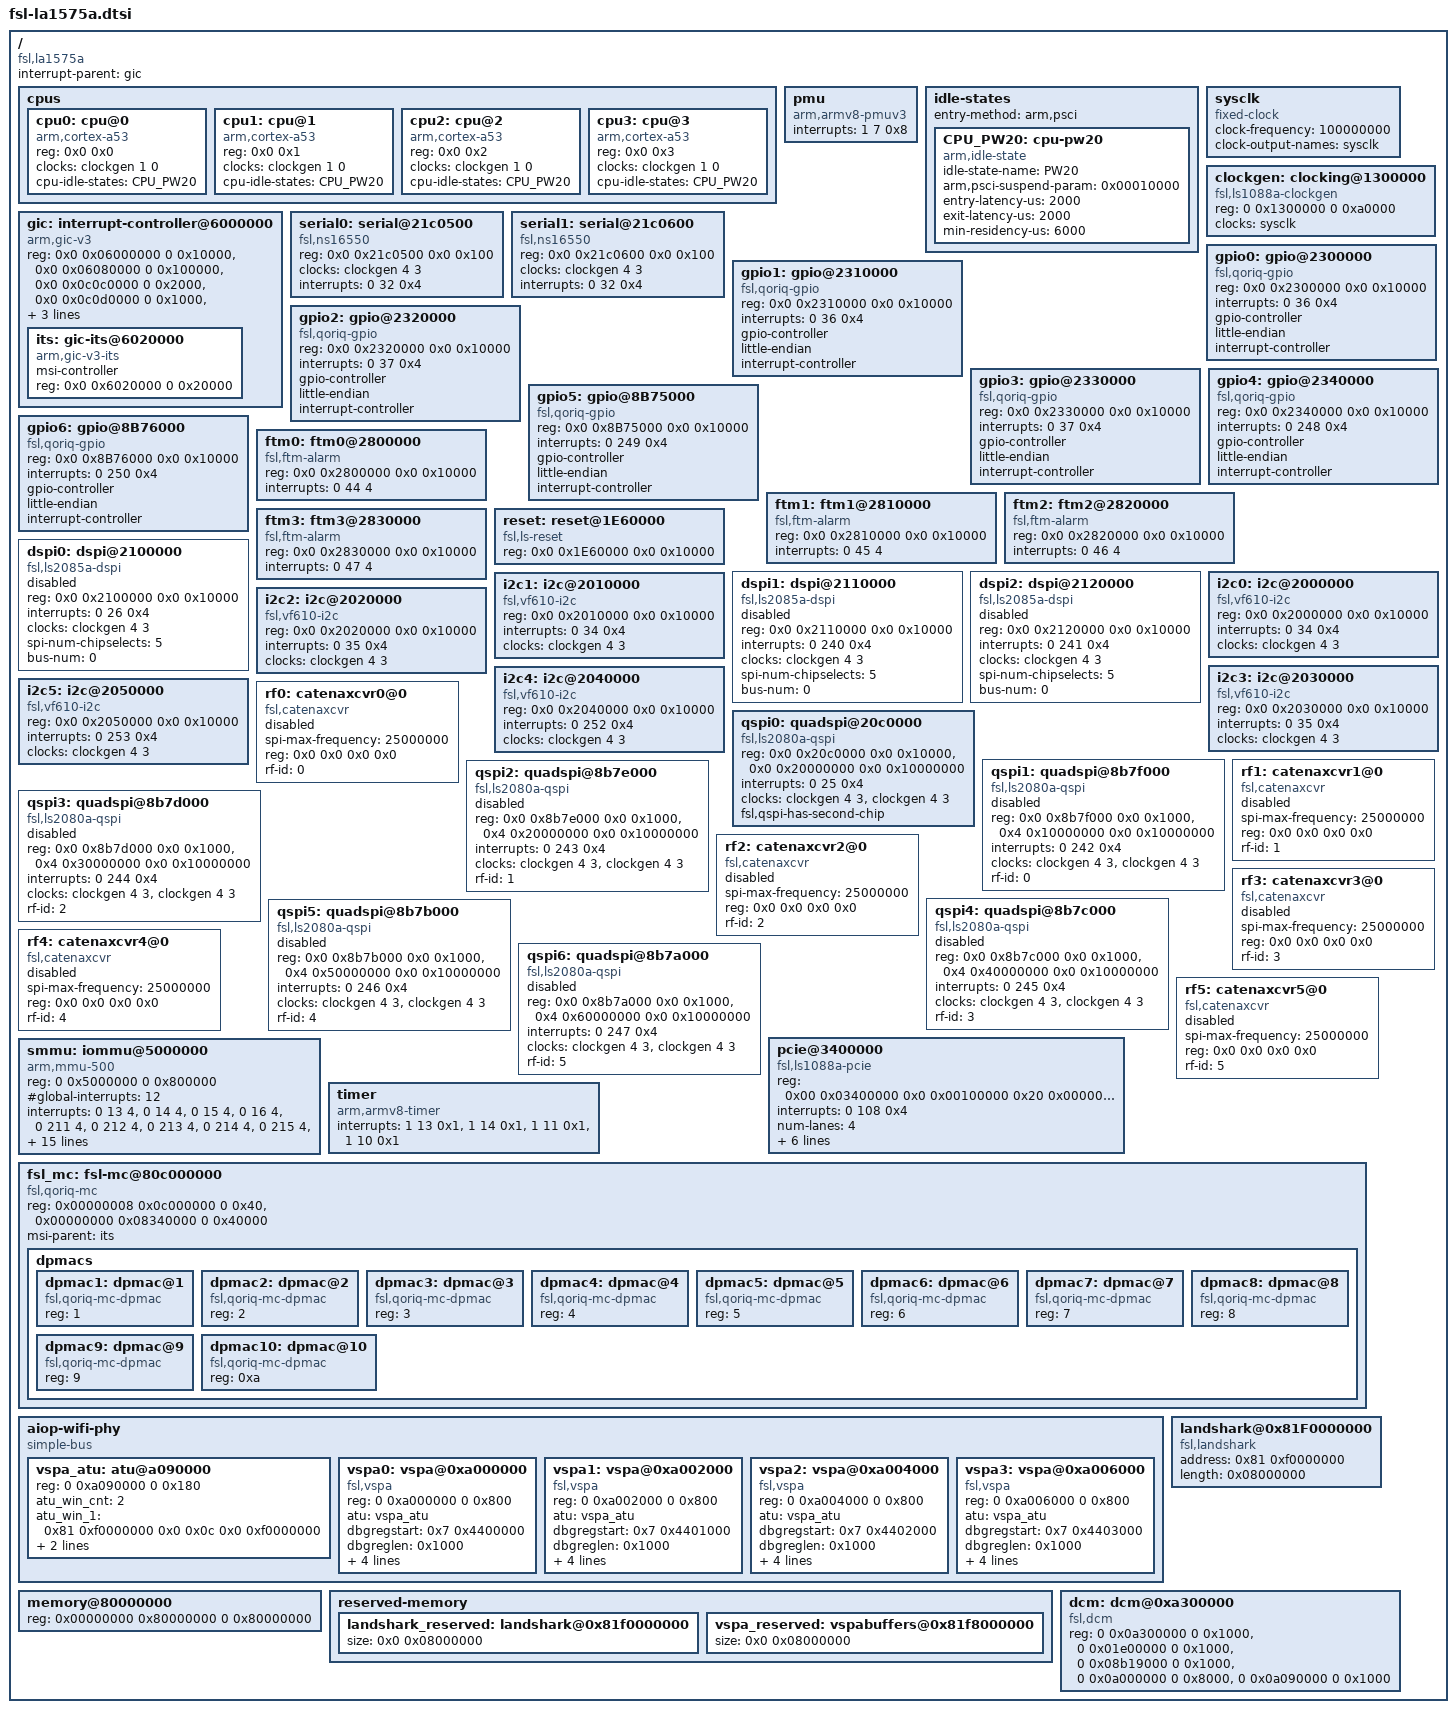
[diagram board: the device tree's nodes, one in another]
/*
 * Device Tree Include file for NXP's LA1575A family SoC.
 *
 * Copyright (C) 2017, Freescale Semiconductor
 *
 * Abhimanyu Saini <abhimanyu.saini@nxp.com>
 * Rajesh Bhagat <rajesh.bhagat@nxp.com>
 *
 * This file is dual-licensed: you can use it either under the terms
 * of the GPLv2 or the X11 license, at your option. Note that this dual
 * licensing only applies to this file, and not this project as a
 * whole.
 *
 *  a) This library is free software; you can redistribute it and/or
 *     modify it under the terms of the GNU General Public License as
 *     published by the Free Software Foundation; either version 2 of the
 *     License, or (at your option) any later version.
 *
 *     This library is distributed in the hope that it will be useful,
 *     but WITHOUT ANY WARRANTY; without even the implied warranty of
 *     MERCHANTABILITY or FITNESS FOR A PARTICULAR PURPOSE.  See the
 *     GNU General Public License for more details.
 *
 * Or, alternatively,
 *
 *  b) Permission is hereby granted, free of charge, to any person
 *     obtaining a copy of this software and associated documentation
 *     files (the "Software"), to deal in the Software without
 *     restriction, including without limitation the rights to use,
 *     copy, modify, merge, publish, distribute, sublicense, and/or
 *     sell copies of the Software, and to permit persons to whom the
 *     Software is furnished to do so, subject to the following
 *     conditions:
 *
 *     The above copyright notice and this permission notice shall be
 *     included in all copies or substantial portions of the Software.
 *
 *     THE SOFTWARE IS PROVIDED "AS IS", WITHOUT WARRANTY OF ANY KIND,
 *     EXPRESS OR IMPLIED, INCLUDING BUT NOT LIMITED TO THE WARRANTIES
 *     OF MERCHANTABILITY, FITNESS FOR A PARTICULAR PURPOSE AND
 *     NONINFRINGEMENT. IN NO EVENT SHALL THE AUTHORS OR COPYRIGHT
 *     HOLDERS BE LIABLE FOR ANY CLAIM, DAMAGES OR OTHER LIABILITY,
 *     WHETHER IN AN ACTION OF CONTRACT, TORT OR OTHERWISE, ARISING
 *     FROM, OUT OF OR IN CONNECTION WITH THE SOFTWARE OR THE USE OR
 *     OTHER DEALINGS IN THE SOFTWARE.
 */

/memreserve/ 0x80000000 0x00010000;

/ {
	compatible = "fsl,la1575a";
	interrupt-parent = <&gic>;
	#address-cells = <2>;
	#size-cells = <2>;

	cpus {
		#address-cells = <2>;
		#size-cells = <0>;

		/* We have 1 cluster having 4 Cortex-A53 cores each */
		cpu0: cpu@0 {
			device_type = "cpu";
			compatible = "arm,cortex-a53";
			reg = <0x0 0x0>;
			clocks = <&clockgen 1 0>;
			cpu-idle-states = <&CPU_PW20>;
		};

		cpu1: cpu@1 {
			device_type = "cpu";
			compatible = "arm,cortex-a53";
			reg = <0x0 0x1>;
			clocks = <&clockgen 1 0>;
			cpu-idle-states = <&CPU_PW20>;
		};

		cpu2: cpu@2 {
			device_type = "cpu";
			compatible = "arm,cortex-a53";
			reg = <0x0 0x2>;
			clocks = <&clockgen 1 0>;
			cpu-idle-states = <&CPU_PW20>;
		};

		cpu3: cpu@3 {
			device_type = "cpu";
			compatible = "arm,cortex-a53";
			reg = <0x0 0x3>;
			clocks = <&clockgen 1 0>;
			cpu-idle-states = <&CPU_PW20>;
		};

	};

	pmu {
		compatible = "arm,armv8-pmuv3";
		interrupts = <1 7 0x8>; /* PMU PPI, Level low type */
	};

	idle-states {
		entry-method = "arm,psci";

		CPU_PW20: cpu-pw20 {
			compatible = "arm,idle-state";
			idle-state-name = "PW20";
			arm,psci-suspend-param = <0x00010000>;
			entry-latency-us = <2000>;
			exit-latency-us = <2000>;
			min-residency-us = <6000>;
		};
	};

	gic: interrupt-controller@6000000 {
		compatible = "arm,gic-v3";
		reg = <0x0 0x06000000 0 0x10000>, /* GIC Dist */
		      <0x0 0x06080000 0 0x100000>, /* GICR(RD_base+SGI_base)*/
		      <0x0 0x0c0c0000 0 0x2000>, /* GICC */
		      <0x0 0x0c0d0000 0 0x1000>, /* GICH */
		      <0x0 0x0c0e0000 0 0x20000>; /* GICV */
		#interrupt-cells = <3>;
		#address-cells = <2>;
		#size-cells = <2>;
		ranges;
		interrupt-controller;
		interrupts = <1 9 0x4>;

		its: gic-its@6020000 {
			compatible = "arm,gic-v3-its";
			msi-controller;
			reg = <0x0 0x6020000 0 0x20000>;
		};
	};

	sysclk: sysclk {
		compatible = "fixed-clock";
		#clock-cells = <0>;
		clock-frequency = <100000000>;
		clock-output-names = "sysclk";
	};

	clockgen: clocking@1300000 {
		compatible = "fsl,ls1088a-clockgen";
		reg = <0 0x1300000 0 0xa0000>;
		#clock-cells = <2>;
		clocks = <&sysclk>;
	};

	serial0: serial@21c0500 {
		device_type = "serial";
		compatible = "fsl,ns16550", "ns16550a";
		reg = <0x0 0x21c0500 0x0 0x100>;
		clocks = <&clockgen 4 3>;
		interrupts = <0 32 0x4>; /* Level high type */
	};

	serial1: serial@21c0600 {
		device_type = "serial";
		compatible = "fsl,ns16550", "ns16550a";
		reg = <0x0 0x21c0600 0x0 0x100>;
		clocks = <&clockgen 4 3>;
		interrupts = <0 32 0x4>; /* Level high type */
	};

	gpio0: gpio@2300000 {
		compatible = "fsl,qoriq-gpio";
		reg = <0x0 0x2300000 0x0 0x10000>;
		interrupts = <0 36 0x4>; /* Level high type */
		gpio-controller;
		little-endian;
		#gpio-cells = <2>;
		interrupt-controller;
		#interrupt-cells = <2>;
	};

	gpio1: gpio@2310000 {
		compatible = "fsl,qoriq-gpio";
		reg = <0x0 0x2310000 0x0 0x10000>;
		interrupts = <0 36 0x4>; /* Level high type */
		gpio-controller;
		little-endian;
		#gpio-cells = <2>;
		interrupt-controller;
		#interrupt-cells = <2>;
	};

	gpio2: gpio@2320000 {
		compatible = "fsl,qoriq-gpio";
		reg = <0x0 0x2320000 0x0 0x10000>;
		interrupts = <0 37 0x4>; /* Level high type */
		gpio-controller;
		little-endian;
		#gpio-cells = <2>;
		interrupt-controller;
		#interrupt-cells = <2>;
	};

	gpio3: gpio@2330000 {
		compatible = "fsl,qoriq-gpio";
		reg = <0x0 0x2330000 0x0 0x10000>;
		interrupts = <0 37 0x4>; /* Level high type */
		gpio-controller;
		little-endian;
		#gpio-cells = <2>;
		interrupt-controller;
		#interrupt-cells = <2>;
	};

	gpio4: gpio@2340000 {
		compatible = "fsl,qoriq-gpio";
		reg = <0x0 0x2340000 0x0 0x10000>;
		interrupts = <0 248 0x4>; /* Level high type */
		gpio-controller;
		little-endian;
		#gpio-cells = <2>;
		interrupt-controller;
		#interrupt-cells = <2>;
	};

	gpio5: gpio@8B75000  {
		compatible = "fsl,qoriq-gpio";
		reg = <0x0 0x8B75000  0x0 0x10000>;
		interrupts = <0 249 0x4>; /* Level high type */
		gpio-controller;
		little-endian;
		#gpio-cells = <2>;
		interrupt-controller;
		#interrupt-cells = <2>;
	};

	gpio6: gpio@8B76000  {
		compatible = "fsl,qoriq-gpio";
		reg = <0x0 0x8B76000  0x0 0x10000>;
		interrupts = <0 250 0x4>; /* Level high type */
		gpio-controller;
		little-endian;
		#gpio-cells = <2>;
		interrupt-controller;
		#interrupt-cells = <2>;
	};

	ftm0: ftm0@2800000 {
		compatible = "fsl,ftm-alarm";
		reg = <0x0 0x2800000 0x0 0x10000>;
		interrupts = <0 44 4>;
	};

	ftm1: ftm1@2810000 {
		compatible = "fsl,ftm-alarm";
		reg = <0x0 0x2810000 0x0 0x10000>;
		interrupts = <0 45 4>;
	};

	ftm2: ftm2@2820000 {
		compatible = "fsl,ftm-alarm";
		reg = <0x0 0x2820000 0x0 0x10000>;
		interrupts = <0 46 4>;
	};

	ftm3: ftm3@2830000 {
		compatible = "fsl,ftm-alarm";
		reg = <0x0 0x2830000 0x0 0x10000>;
		interrupts = <0 47 4>;
	};

	reset: reset@1E60000 {
		compatible = "fsl,ls-reset";
		reg = <0x0 0x1E60000 0x0 0x10000>;
	};

	dspi0: dspi@2100000 {
		compatible = "fsl,ls2085a-dspi";
		#address-cells = <1>;
		#size-cells = <0>;
		reg = <0x0 0x2100000 0x0 0x10000>;
		interrupts = <0 26 0x4>; /* Level high type */
		clocks = <&clockgen 4 3>;
		clock-names = "dspi";
		spi-num-chipselects = <5>;
		bus-num = <0>;
		status = "disabled";
	};

	dspi1: dspi@2110000 {
		compatible = "fsl,ls2085a-dspi";
		#address-cells = <1>;
		#size-cells = <0>;
		reg = <0x0 0x2110000 0x0 0x10000>;
		interrupts = <0 240 0x4>; /* Level high type */
		clocks = <&clockgen 4 3>;
		clock-names = "dspi";
		spi-num-chipselects = <5>;
		bus-num = <0>;
		status = "dspi";
	};

	dspi2: dspi@2120000 {
		compatible = "fsl,ls2085a-dspi";
		#address-cells = <1>;
		#size-cells = <0>;
		reg = <0x0 0x2120000 0x0 0x10000>;
		interrupts = <0 241 0x4>; /* Level high type */
		clocks = <&clockgen 4 3>;
		clock-names = "dspi";
		spi-num-chipselects = <5>;
		bus-num = <0>;
		status = "disabled";
	};

	i2c0: i2c@2000000 {
		compatible = "fsl,vf610-i2c";
		#address-cells = <1>;
		#size-cells = <0>;
		reg = <0x0 0x2000000 0x0 0x10000>;
		interrupts = <0 34 0x4>; /* Level high type */
		clock-names = "i2c";
		clocks = <&clockgen 4 3>;
	};

	i2c1: i2c@2010000 {
		compatible = "fsl,vf610-i2c";
		#address-cells = <1>;
		#size-cells = <0>;
		reg = <0x0 0x2010000 0x0 0x10000>;
		interrupts = <0 34 0x4>; /* Level high type */
		clock-names = "i2c";
		clocks = <&clockgen 4 3>;
	};

	i2c2: i2c@2020000 {
		compatible = "fsl,vf610-i2c";
		#address-cells = <1>;
		#size-cells = <0>;
		reg = <0x0 0x2020000 0x0 0x10000>;
		interrupts = <0 35 0x4>; /* Level high type */
		clock-names = "i2c";
		clocks = <&clockgen 4 3>;
	};

	i2c3: i2c@2030000 {
		compatible = "fsl,vf610-i2c";
		#address-cells = <1>;
		#size-cells = <0>;
		reg = <0x0 0x2030000 0x0 0x10000>;
		interrupts = <0 35 0x4>; /* Level high type */
		clock-names = "i2c";
		clocks = <&clockgen 4 3>;
	};

	i2c4: i2c@2040000 {
		compatible = "fsl,vf610-i2c";
		#address-cells = <1>;
		#size-cells = <0>;
		reg = <0x0 0x2040000 0x0 0x10000>;
		interrupts = <0 252 0x4>; /* Level high type */
		clock-names = "i2c";
		clocks = <&clockgen 4 3>;
		status = "okay";
	};

	i2c5: i2c@2050000 {
		compatible = "fsl,vf610-i2c";
		#address-cells = <1>;
		#size-cells = <0>;
		reg = <0x0 0x2050000 0x0 0x10000>;
		interrupts = <0 253 0x4>; /* Level high type */
		clock-names = "i2c";
		clocks = <&clockgen 4 3>;
		status = "okay";
	};

	qspi0: quadspi@20c0000 {
		compatible = "fsl,ls2080a-qspi", "fsl,la1575a-qspi";
		#address-cells = <1>;
		#size-cells = <0>;
		reg = <0x0 0x20c0000 0x0 0x10000>,
		      <0x0 0x20000000 0x0 0x10000000>;
		reg-names = "QuadSPI", "QuadSPI-memory";
		interrupts = <0 25 0x4>; /* Level high type */
		clocks = <&clockgen 4 3>, <&clockgen 4 3>;
		clock-names = "qspi_en", "qspi";
		fsl,qspi-has-second-chip;
		status = "okay";
	};

	qspi1: quadspi@8b7f000 {
		compatible = "fsl,ls2080a-qspi", "fsl,ua-qspi";
		#address-cells = <1>;
		#size-cells = <0>;
		reg = <0x0 0x8b7f000 0x0 0x1000>,
		      <0x4 0x10000000 0x0 0x10000000>;
		reg-names = "QuadSPI", "QuadSPI-memory";
		interrupts = <0 242 0x4>; /* Level high type */
		clocks = <&clockgen 4 3>, <&clockgen 4 3>;
		clock-names = "qspi_en", "qspi";
		rf-id = <0>;
		status = "disabled";
	};

	rf0: catenaxcvr0@0 {
		compatible = "fsl,catenaxcvr";
		spi-max-frequency = <25000000>;
		reg = <0x0 0x0 0x0 0x0>;
		rf-id = <0>;
		status = "disabled";
	};

	qspi2: quadspi@8b7e000 {
		compatible = "fsl,ls2080a-qspi", "fsl,ua-qspi";
		#address-cells = <1>;
		#size-cells = <0>;
		reg = <0x0 0x8b7e000 0x0 0x1000>,
		      <0x4 0x20000000 0x0 0x10000000>;
		reg-names = "QuadSPI", "QuadSPI-memory";
		interrupts = <0 243 0x4>; /* Level high type */
		clocks = <&clockgen 4 3>, <&clockgen 4 3>;
		clock-names = "qspi_en", "qspi";
		rf-id = <1>;
		status = "disabled";
	};

	rf1: catenaxcvr1@0 {
		compatible = "fsl,catenaxcvr";
		spi-max-frequency = <25000000>;
		reg = <0x0 0x0 0x0 0x0>;
		rf-id = <1>;
		status = "disabled";
	};

	qspi3: quadspi@8b7d000 {
		compatible = "fsl,ls2080a-qspi", "fsl,ua-qspi";
		#address-cells = <1>;
		#size-cells = <0>;
		reg = <0x0 0x8b7d000 0x0 0x1000>,
		      <0x4 0x30000000 0x0 0x10000000>;
		reg-names = "QuadSPI", "QuadSPI-memory";
		interrupts = <0 244 0x4>; /* Level high type */
		clocks = <&clockgen 4 3>, <&clockgen 4 3>;
		clock-names = "qspi_en", "qspi";
		rf-id = <2>;
		status = "disabled";
	};

	rf2: catenaxcvr2@0 {
		compatible = "fsl,catenaxcvr";
		spi-max-frequency = <25000000>;
		reg = <0x0 0x0 0x0 0x0>;
		rf-id = <2>;
		status = "disabled";
	};

	qspi4: quadspi@8b7c000 {
		compatible = "fsl,ls2080a-qspi", "fsl,ua-qspi";
		#address-cells = <1>;
		#size-cells = <0>;
		reg = <0x0 0x8b7c000 0x0 0x1000>,
		      <0x4 0x40000000 0x0 0x10000000>;
		reg-names = "QuadSPI", "QuadSPI-memory";
		interrupts = <0 245 0x4>; /* Level high type */
		clocks = <&clockgen 4 3>, <&clockgen 4 3>;
		clock-names = "qspi_en", "qspi";
		rf-id = <3>;
		status = "disabled";
	};

	rf3: catenaxcvr3@0 {
		compatible = "fsl,catenaxcvr";
		spi-max-frequency = <25000000>;
		reg = <0x0 0x0 0x0 0x0>;
		rf-id = <3>;
		status = "disabled";
	};

	qspi5: quadspi@8b7b000 {
		compatible = "fsl,ls2080a-qspi", "fsl,ua-qspi";
		#address-cells = <1>;
		#size-cells = <0>;
		reg = <0x0 0x8b7b000 0x0 0x1000>,
		      <0x4 0x50000000 0x0 0x10000000>;
		reg-names = "QuadSPI", "QuadSPI-memory";
		interrupts = <0 246 0x4>; /* Level high type */
		clocks = <&clockgen 4 3>, <&clockgen 4 3>;
		clock-names = "qspi_en", "qspi";
		rf-id = <4>;
		status = "disabled";
	};

	rf4: catenaxcvr4@0 {
		compatible = "fsl,catenaxcvr";
		spi-max-frequency = <25000000>;
		reg = <0x0 0x0 0x0 0x0>;
		rf-id = <4>;
		status = "disabled";
	};

	qspi6: quadspi@8b7a000 {
		compatible = "fsl,ls2080a-qspi", "fsl,ua-qspi";
		#address-cells = <1>;
		#size-cells = <0>;
		reg = <0x0 0x8b7a000 0x0 0x1000>,
		      <0x4 0x60000000 0x0 0x10000000>;
		reg-names = "QuadSPI", "QuadSPI-memory";
		interrupts = <0 247 0x4>; /* Level high type */
		clocks = <&clockgen 4 3>, <&clockgen 4 3>;
		clock-names = "qspi_en", "qspi";
		rf-id = <5>;
		status = "disabled";
	};

	rf5: catenaxcvr5@0 {
		compatible = "fsl,catenaxcvr";
		spi-max-frequency = <25000000>;
		reg = <0x0 0x0 0x0 0x0>;
		rf-id = <5>;
		status = "disabled";
	};

	pcie@3400000 {
		compatible = "fsl,ls1088a-pcie", "snps,dw-pcie";
		reg = <0x00 0x03400000 0x0 0x00100000
		       0x20 0x00000000 0x0 0x00002000>;
		reg-names = "regs", "config";
		interrupts = <0 108 0x4>; /* aer interrupt */
		interrupt-names = "aer";
		#address-cells = <3>;
		#size-cells = <2>;
		device_type = "pci";
		num-lanes = <4>;
		bus-range = <0x0 0xff>;
		ranges = <0x81000000 0x0 0x00000000 0x20 0x00010000 0x0 0x00010000
			  0x82000000 0x0 0x40000000 0x20 0x40000000 0x0 0x40000000>;
		msi-parent = <&its>;
		#interrupt-cells = <1>;
		interrupt-map-mask = <0 0 0 7>;
		interrupt-map = <0000 0 0 1 &gic 0 0 0 109 4>,
				<0000 0 0 2 &gic 0 0 0 110 4>,
				<0000 0 0 3 &gic 0 0 0 111 4>,
				<0000 0 0 4 &gic 0 0 0 112 4>;
		status = "okay";
	};

	smmu: iommu@5000000 {
		compatible = "arm,mmu-500";
		reg = <0 0x5000000 0 0x800000>;
		#global-interrupts = <12>;
		interrupts = <0 13 4>, /* global secure fault */
			     <0 14 4>, /* combined secure interrupt */
			     <0 15 4>, /* global non-secure fault */
			     <0 16 4>, /* combined non-secure interrupt */
			/* performance counter interrupts 0-7 */
			     <0 211 4>,
			     <0 212 4>,
			     <0 213 4>,
			     <0 214 4>,
			     <0 215 4>,
			     <0 216 4>,
			     <0 217 4>,
			     <0 218 4>,
			/* per context interrupt, 64 interrupts */
			     <0 146 4>,
			     <0 147 4>,
			     <0 148 4>,
			     <0 149 4>,
			     <0 150 4>,
			     <0 151 4>,
			     <0 152 4>,
			     <0 153 4>,
			     <0 154 4>,
			     <0 155 4>,
			     <0 156 4>,
			     <0 157 4>,
			     <0 158 4>,
			     <0 159 4>,
			     <0 160 4>,
			     <0 161 4>,
			     <0 162 4>,
			     <0 163 4>,
			     <0 164 4>,
			     <0 165 4>,
			     <0 166 4>,
			     <0 167 4>,
			     <0 168 4>,
			     <0 169 4>,
			     <0 170 4>,
			     <0 171 4>,
			     <0 172 4>,
			     <0 173 4>,
			     <0 174 4>,
			     <0 175 4>,
			     <0 176 4>,
			     <0 177 4>,
			     <0 178 4>,
			     <0 179 4>,
			     <0 180 4>,
			     <0 181 4>,
			     <0 182 4>,
			     <0 183 4>,
			     <0 184 4>,
			     <0 185 4>,
			     <0 186 4>,
			     <0 187 4>,
			     <0 188 4>,
			     <0 189 4>,
			     <0 190 4>,
			     <0 191 4>,
			     <0 192 4>,
			     <0 193 4>,
			     <0 194 4>,
			     <0 195 4>,
			     <0 196 4>,
			     <0 197 4>,
			     <0 198 4>,
			     <0 199 4>,
			     <0 200 4>,
			     <0 201 4>,
			     <0 202 4>,
			     <0 203 4>,
			     <0 204 4>,
			     <0 205 4>,
			     <0 206 4>,
			     <0 207 4>,
			     <0 208 4>,
			     <0 209 4>;
		mmu-masters = <&fsl_mc 0x300 0>;
	};

	timer {
		compatible = "arm,armv8-timer";
		interrupts = <1 13 0x1>,/*Phy Secure PPI, edge triggered*/
			     <1 14 0x1>, /*Phy Non-Secure PPI, edge triggered*/
			     <1 11 0x1>, /*Virtual PPI, edge triggered */
			     <1 10 0x1>; /*Hypervisor PPI, edge triggered */
	};

	fsl_mc: fsl-mc@80c000000 {
		compatible = "fsl,qoriq-mc";
		#stream-id-cells = <2>;
		reg = <0x00000008 0x0c000000 0 0x40>,	 /* MC portal base */
		      <0x00000000 0x08340000 0 0x40000>; /* MC control reg */
		msi-parent = <&its>;
		#address-cells = <3>;
		#size-cells = <1>;

		/*
		 * Region type 0x0 - MC portals
		 * Region type 0x1 - QBMAN portals
		 */
		ranges = <0x0 0x0 0x0 0x8 0x0c000000 0x4000000
			  0x1 0x0 0x0 0x8 0x18000000 0x8000000>;

		dpmacs {
			#address-cells = <1>;
			#size-cells = <0>;

			dpmac1: dpmac@1 {
				compatible = "fsl,qoriq-mc-dpmac";
				reg = <1>;
			};
			dpmac2: dpmac@2 {
				compatible = "fsl,qoriq-mc-dpmac";
				reg = <2>;
			};
			dpmac3: dpmac@3 {
				compatible = "fsl,qoriq-mc-dpmac";
				reg = <3>;
			};
			dpmac4: dpmac@4 {
				compatible = "fsl,qoriq-mc-dpmac";
				reg = <4>;
			};
			dpmac5: dpmac@5 {
				compatible = "fsl,qoriq-mc-dpmac";
				reg = <5>;
			};
			dpmac6: dpmac@6 {
				compatible = "fsl,qoriq-mc-dpmac";
				reg = <6>;
			};
			dpmac7: dpmac@7 {
				compatible = "fsl,qoriq-mc-dpmac";
				reg = <7>;
			};
			dpmac8: dpmac@8 {
				compatible = "fsl,qoriq-mc-dpmac";
				reg = <8>;
			};
			dpmac9: dpmac@9 {
				compatible = "fsl,qoriq-mc-dpmac";
				reg = <9>;
			};
			dpmac10: dpmac@10 {
				compatible = "fsl,qoriq-mc-dpmac";
				reg = <0xa>;
			};
		};
	};


	aiop-wifi-phy {
		compatible = "simple-bus";
		#address-cells = <2>;
		#size-cells = <2>;
		ranges;

		vspa_atu: atu@a090000 {
			/* VSPA ATU has 7 + 1 translation
				Windows */
			reg = <0 0xa090000 0 0x180>;
			/* Number of ATU windows to be used */
			atu_win_cnt = <2>;
			/* ATU Windows Entry Format:
			* Maximum Window size supported by ATU is 2GB
			* atu_win_<n> =
			*	< <64 Bit SoC Address> <Window Size> <Mapped Address> >
			*/

			/*	Value Window Size
			*	00000 64 KB
			*	00001 128 KB
			*	00010 256 KB
			*	00011 512 KB
			*	00100 1 MB
			*	00101 2 MB
			*	00110 4 MB
			*	00111 8 MB
			*	01000 16 MB
			*	01001 32 MB
			*	01010 64 MB
			*	01011 128 MB
			*	01100 256 MB
			*	01101 512 MB
			*	01110 1 GB
			*	01111 2 GB
			*	1xxxx Reserved
			*/
			atu_win_1 = <0x81 0xf0000000 0x0 0x0c 0x0 0xf0000000>;
			atu_win_2 = <0x4c 0x04000000 0x0 0x05 0x0 0x54000000>;
		};

		vspa0: vspa@0xa000000 {
			compatible = "fsl,vspa";
			reg = <0 0xa000000 0 0x800>;

			atu = <&vspa_atu>;

			dbgregstart = <0x7 0x4400000>;
			dbgreglen = <0x1000>;

			vspadev-id  = <0>;
			interrupts = <0 232 0x4>;
			status = "okay";

			shbufstart = <0x81 0xf8000000>;
			shbuflen = <0x08000000>;
		};

		vspa1: vspa@0xa002000 {
			compatible = "fsl,vspa";
			reg = <0 0xa002000 0 0x800>;

			atu = <&vspa_atu>;

			dbgregstart = <0x7 0x4401000>;
			dbgreglen = <0x1000>;

			vspadev-id  = <1>;
			interrupts = <0 233 0x4>;
			status = "okay";

			shbufstart = <0x81 0xf8000000>;
			shbuflen = <0x08000000>;
		};

		vspa2: vspa@0xa004000 {
			compatible = "fsl,vspa";
			reg = <0 0xa004000 0 0x800>;

			atu = <&vspa_atu>;

			dbgregstart = <0x7 0x4402000>;
			dbgreglen = <0x1000>;

			vspadev-id  = <2>;
			interrupts = <0 234 0x4>;
			status = "okay";

			shbufstart = <0x81 0xf8000000>;
			shbuflen = <0x08000000>;
		};

		vspa3: vspa@0xa006000 {
			compatible = "fsl,vspa";
			reg = <0 0xa006000 0 0x800>;

			atu = <&vspa_atu>;

			dbgregstart = <0x7 0x4403000>;
			dbgreglen = <0x1000>;

			vspadev-id  = <3>;
			interrupts = <0 235 0x4>;
			status = "okay";

			shbufstart = <0x81 0xf8000000>;
			shbuflen = <0x08000000>;
		};
	};

	memory@80000000 {
		device_type = "memory";
		reg = <0x00000000 0x80000000 0 0x80000000>;
		      /* DRAM space 1 - 2 GB DRAM */
	};

	reserved-memory {
		#address-cells = <2>;
		#size-cells = <2>;
		ranges;

		landshark_reserved: landshark@0x81f0000000 {
			size = <0x0 0x08000000>;
		};

		vspa_reserved: vspabuffers@0x81f8000000 {
			size = <0x0 0x08000000>;
		};
	};

	landshark@0x81F0000000 {
		compatible = "fsl,landshark";
		address = <0x81 0xf0000000>;
		length = <0x08000000>;
	};

	dcm: dcm@0xa300000 {
		compatible = "fsl,dcm";
		reg = <0 0x0a300000 0 0x1000>,
		    <0 0x01e00000 0 0x1000>,
		    <0 0x08b19000 0 0x1000>,
		    <0 0x0a000000 0 0x8000>,
		    <0 0x0a090000 0 0x1000>;
	};
};
